AUTOSAR XML (schema 4-1-3)
standard types defined: boolean, uint16, uint8
package /UAES/ASW/ApplicationDataTypes
  app type Curr_Ampr_u16: category=VALUE, sw-calibration-access=READ-WRITE, compu {phys=raw*0.1; unit A}, range raw 0..65535, unit=A
package /UAES/ASW/CompuMethods
  compu method CM_boolean: 0=FALSE, 1=TRUE
package /UAES/ASW/DataTypeMappingSets
  data type mapping set DTMS_KL15PwrSplyComCnvRx: data-type-map{application-data-type=Curr_Ampr_u16, implementation-data-type=uint16}
  data type mapping set DTMS_ZCUTAdpr: data-type-map{application-data-type=Curr_Ampr_u16, implementation-data-type=uint16}
package /UAES/ASW/ImplementationDataTypes
  impl type rt_Array_uint8_29: category=ARRAY
    element rt_Array_uint8_29: array-size=29, array-size-semantics=FIXED-SIZE, implementation-data-type=uint8
package /UAES/ASW/PortInterfaces
  client server interface NMW_tGetAllCurrentComModeRTE
    operation Operation: possible-error=NMW_tGetAllCurrentComModeRTE/NmChannelIndexError
      arg Status: type=boolean, direction=OUT, server-argument-impl-policy=USE-ARGUMENT-TYPE
    error NmChannelIndexError: error-code=1
  client server interface NMW_tGetCurrentComModeRTE
    operation Operation: possible-error=NMW_tGetCurrentComModeRTE/NmChannelIndexError
      arg ComMChannel: type=uint8, direction=IN, server-argument-impl-policy=USE-ARGUMENT-TYPE
      arg ChannelStatus: type=boolean, direction=OUT, server-argument-impl-policy=USE-ARGUMENT-TYPE
    error NmChannelIndexError: error-code=1
  95 x sender receiver interface:
    ComRx_bBCS_VehSpd_TiOut: invalidation-policy{data-element=ComRx_bBCS_VehSpd_TiOut/Val, handle-invalid=DONT-INVALIDATE}
      data Val: sw-calibration-access=READ-ONLY, range raw 0..1, type=boolean
    ComRx_bBCS_VehSpdVD: invalidation-policy{data-element=ComRx_bBCS_VehSpdVD/Val, handle-invalid=DONT-INVALIDATE}
      data Val: sw-calibration-access=READ-ONLY, type=boolean
    ComRx_bBCS_VehSpdVD_TiOut: invalidation-policy{data-element=ComRx_bBCS_VehSpdVD_TiOut/Val, handle-invalid=DONT-INVALIDATE}
      data Val: sw-calibration-access=READ-ONLY, range raw 0..1, type=boolean
    ComRx_bEL_PositionLightTimingOFFCfg: invalidation-policy{data-element=ComRx_bEL_PositionLightTimingOFFCfg/Val, handle-invalid=DONT-INVALIDATE}
      data Val: sw-calibration-access=READ-ONLY, type=boolean
    ComRx_bEL_RLPositionLightCtrlCmd: invalidation-policy{data-element=ComRx_bEL_RLPositionLightCtrlCmd/Val, handle-invalid=DONT-INVALIDATE}
      data Val: sw-calibration-access=READ-ONLY, type=boolean
    ComRx_bEL_RRPositionLightCtrlCmd: invalidation-policy{data-element=ComRx_bEL_RRPositionLightCtrlCmd/Val, handle-invalid=DONT-INVALIDATE}
      data Val: sw-calibration-access=READ-ONLY, type=boolean
    ComRx_bIPDS_AMPPowerSup_TiOut: invalidation-policy{data-element=ComRx_bIPDS_AMPPowerSup_TiOut/Val, handle-invalid=DONT-INVALIDATE}
      data Val: sw-calibration-access=READ-ONLY, range raw 0..1, type=boolean
    ComRx_bIPDS_InverterPowerSup_TiOut: invalidation-policy{data-element=ComRx_bIPDS_InverterPowerSup_TiOut/Val, handle-invalid=DONT-INVALIDATE}
      data Val: sw-calibration-access=READ-ONLY, range raw 0..1, type=boolean
    ComRx_bIPDS_KL15T1PowerSup_TiOut: invalidation-policy{data-element=ComRx_bIPDS_KL15T1PowerSup_TiOut/Val, handle-invalid=DONT-INVALIDATE}
      data Val: sw-calibration-access=READ-ONLY, range raw 0..1, type=boolean
    ComRx_bIPDS_KL15T2PowerSup_TiOut: invalidation-policy{data-element=ComRx_bIPDS_KL15T2PowerSup_TiOut/Val, handle-invalid=DONT-INVALIDATE}
      data Val: sw-calibration-access=READ-ONLY, range raw 0..1, type=boolean
    ComRx_bIPDS_PCUPowerSup_TiOut: invalidation-policy{data-element=ComRx_bIPDS_PCUPowerSup_TiOut/Val, handle-invalid=DONT-INVALIDATE}
      data Val: sw-calibration-access=READ-ONLY, range raw 0..1, type=boolean
    ComRx_bIPDS_Rear12VPowerSup_TiOut: invalidation-policy{data-element=ComRx_bIPDS_Rear12VPowerSup_TiOut/Val, handle-invalid=DONT-INVALIDATE}
      data Val: sw-calibration-access=READ-ONLY, range raw 0..1, type=boolean
    ComRx_bIPDS_RearBlowerPowerSup_TiOut: invalidation-policy{data-element=ComRx_bIPDS_RearBlowerPowerSup_TiOut/Val, handle-invalid=DONT-INVALIDATE}
      data Val: sw-calibration-access=READ-ONLY, range raw 0..1, type=boolean
    ComRx_bIPDS_RearCtrlPanelPowerSup_TiOut: invalidation-policy{data-element=ComRx_bIPDS_RearCtrlPanelPowerSup_TiOut/Val, handle-invalid=DONT-INVALIDATE}
      data Val: sw-calibration-access=READ-ONLY, range raw 0..1, type=boolean
    ComRx_bIPDS_RearEOPPowerSup_TiOut: invalidation-policy{data-element=ComRx_bIPDS_RearEOPPowerSup_TiOut/Val, handle-invalid=DONT-INVALIDATE}
      data Val: sw-calibration-access=READ-ONLY, range raw 0..1, type=boolean
    ComRx_bIPDS_RearMotorPowerSup_TiOut: invalidation-policy{data-element=ComRx_bIPDS_RearMotorPowerSup_TiOut/Val, handle-invalid=DONT-INVALIDATE}
      data Val: sw-calibration-access=READ-ONLY, range raw 0..1, type=boolean
    ComRx_bIPDS_RearRadarPowerSup_TiOut: invalidation-policy{data-element=ComRx_bIPDS_RearRadarPowerSup_TiOut/Val, handle-invalid=DONT-INVALIDATE}
      data Val: sw-calibration-access=READ-ONLY, range raw 0..1, type=boolean
    ComRx_bIPDS_RLALampCtlUnitPowerSup_TiOut: invalidation-policy{data-element=ComRx_bIPDS_RLALampCtlUnitPowerSup_TiOut/Val, handle-invalid=DONT-INVALIDATE}
      data Val: sw-calibration-access=READ-ONLY, range raw 0..1, type=boolean
    ComRx_bIPDS_RLBLampCtlUnitPowerSup_TiOut: invalidation-policy{data-element=ComRx_bIPDS_RLBLampCtlUnitPowerSup_TiOut/Val, handle-invalid=DONT-INVALIDATE}
      data Val: sw-calibration-access=READ-ONLY, range raw 0..1, type=boolean
    ComRx_bIPDS_RMPowerSup_TiOut: invalidation-policy{data-element=ComRx_bIPDS_RMPowerSup_TiOut/Val, handle-invalid=DONT-INVALIDATE}
      data Val: sw-calibration-access=READ-ONLY, range raw 0..1, type=boolean
    ComRx_bIPDS_RRALampCtlUnitPowerSup_TiOut: invalidation-policy{data-element=ComRx_bIPDS_RRALampCtlUnitPowerSup_TiOut/Val, handle-invalid=DONT-INVALIDATE}
      data Val: sw-calibration-access=READ-ONLY, range raw 0..1, type=boolean
    ComRx_bIPDS_RRBLampCtlUnitPowerSup_TiOut: invalidation-policy{data-element=ComRx_bIPDS_RRBLampCtlUnitPowerSup_TiOut/Val, handle-invalid=DONT-INVALIDATE}
      data Val: sw-calibration-access=READ-ONLY, range raw 0..1, type=boolean
    ComRx_bUMM_UsageModeSt_TiOut: invalidation-policy{data-element=ComRx_bUMM_UsageModeSt_TiOut/Val, handle-invalid=DONT-INVALIDATE}
      data Val: sw-calibration-access=READ-ONLY, range raw 0..1, type=boolean
    ComRx_u16BCS_VehSpd: invalidation-policy{data-element=ComRx_u16BCS_VehSpd/Val, handle-invalid=DONT-INVALIDATE}
      data Val: sw-calibration-access=READ-ONLY, type=uint16
    ComRx_u8IPDS_AMPPowerSup: invalidation-policy{data-element=ComRx_u8IPDS_AMPPowerSup/Val, handle-invalid=DONT-INVALIDATE}
      data Val: sw-calibration-access=READ-ONLY, range raw 0..255, type=uint8
    ComRx_u8IPDS_AMPPowerSupTime: invalidation-policy{data-element=ComRx_u8IPDS_AMPPowerSupTime/Val, handle-invalid=DONT-INVALIDATE}
      data Val: sw-calibration-access=READ-ONLY, range raw 0..255, type=uint8
    ComRx_u8IPDS_AMPPowerSupTime_RcvCnt: invalidation-policy{data-element=ComRx_u8IPDS_AMPPowerSupTime_RcvCnt/Val, handle-invalid=DONT-INVALIDATE}
      data Val: sw-calibration-access=READ-ONLY, range raw 0..255, type=uint8
    ComRx_u8IPDS_InverterPowerSup: invalidation-policy{data-element=ComRx_u8IPDS_InverterPowerSup/Val, handle-invalid=DONT-INVALIDATE}
      data Val: sw-calibration-access=READ-ONLY, range raw 0..255, type=uint8
    ComRx_u8IPDS_InverterPowerSupTime: invalidation-policy{data-element=ComRx_u8IPDS_InverterPowerSupTime/Val, handle-invalid=DONT-INVALIDATE}
      data Val: sw-calibration-access=READ-ONLY, range raw 0..255, type=uint8
    ComRx_u8IPDS_InverterPowerSupTime_RcvCnt: invalidation-policy{data-element=ComRx_u8IPDS_InverterPowerSupTime_RcvCnt/Val, handle-invalid=DONT-INVALIDATE}
      data Val: sw-calibration-access=READ-ONLY, range raw 0..255, type=uint8
    ComRx_u8IPDS_KL15T1PowerSup: invalidation-policy{data-element=ComRx_u8IPDS_KL15T1PowerSup/Val, handle-invalid=DONT-INVALIDATE}
      data Val: sw-calibration-access=READ-ONLY, range raw 0..255, type=uint8
    ComRx_u8IPDS_KL15T1PowerSupTime: invalidation-policy{data-element=ComRx_u8IPDS_KL15T1PowerSupTime/Val, handle-invalid=DONT-INVALIDATE}
      data Val: sw-calibration-access=READ-ONLY, range raw 0..255, type=uint8
    ComRx_u8IPDS_KL15T1PowerSupTime_RcvCnt: invalidation-policy{data-element=ComRx_u8IPDS_KL15T1PowerSupTime_RcvCnt/Val, handle-invalid=DONT-INVALIDATE}
      data Val: sw-calibration-access=READ-ONLY, range raw 0..255, type=uint8
    ComRx_u8IPDS_KL15T2PowerSup: invalidation-policy{data-element=ComRx_u8IPDS_KL15T2PowerSup/Val, handle-invalid=DONT-INVALIDATE}
      data Val: sw-calibration-access=READ-ONLY, range raw 0..255, type=uint8
    ComRx_u8IPDS_KL15T2PowerSupTime: invalidation-policy{data-element=ComRx_u8IPDS_KL15T2PowerSupTime/Val, handle-invalid=DONT-INVALIDATE}
      data Val: sw-calibration-access=READ-ONLY, range raw 0..255, type=uint8
    ComRx_u8IPDS_KL15T2PowerSupTime_RcvCnt: invalidation-policy{data-element=ComRx_u8IPDS_KL15T2PowerSupTime_RcvCnt/Val, handle-invalid=DONT-INVALIDATE}
      data Val: sw-calibration-access=READ-ONLY, range raw 0..255, type=uint8
    ComRx_u8IPDS_PASPowerSup: invalidation-policy{data-element=ComRx_u8IPDS_PASPowerSup/Val, handle-invalid=DONT-INVALIDATE}
      data Val: sw-calibration-access=READ-ONLY, range raw 0..255, type=uint8
    ComRx_u8IPDS_PASPowerSupTime: invalidation-policy{data-element=ComRx_u8IPDS_PASPowerSupTime/Val, handle-invalid=DONT-INVALIDATE}
      data Val: sw-calibration-access=READ-ONLY, range raw 0..255, type=uint8
    ComRx_u8IPDS_PASPowerSupTime_RcvCnt: invalidation-policy{data-element=ComRx_u8IPDS_PASPowerSupTime_RcvCnt/Val, handle-invalid=DONT-INVALIDATE}
      data Val: sw-calibration-access=READ-ONLY, range raw 0..255, type=uint8
    ComRx_u8IPDS_PCUPowerSup: invalidation-policy{data-element=ComRx_u8IPDS_PCUPowerSup/Val, handle-invalid=DONT-INVALIDATE}
      data Val: sw-calibration-access=READ-ONLY, range raw 0..255, type=uint8
    ComRx_u8IPDS_PCUPowerSupTime: invalidation-policy{data-element=ComRx_u8IPDS_PCUPowerSupTime/Val, handle-invalid=DONT-INVALIDATE}
      data Val: sw-calibration-access=READ-ONLY, range raw 0..255, type=uint8
    ComRx_u8IPDS_PCUPowerSupTime_RcvCnt: invalidation-policy{data-element=ComRx_u8IPDS_PCUPowerSupTime_RcvCnt/Val, handle-invalid=DONT-INVALIDATE}
      data Val: sw-calibration-access=READ-ONLY, range raw 0..255, type=uint8
    ComRx_u8IPDS_Rear12VPowerSup: invalidation-policy{data-element=ComRx_u8IPDS_Rear12VPowerSup/Val, handle-invalid=DONT-INVALIDATE}
      data Val: sw-calibration-access=READ-ONLY, range raw 0..255, type=uint8
    ComRx_u8IPDS_Rear12VPowerSupTime: invalidation-policy{data-element=ComRx_u8IPDS_Rear12VPowerSupTime/Val, handle-invalid=DONT-INVALIDATE}
      data Val: sw-calibration-access=READ-ONLY, range raw 0..255, type=uint8
    ComRx_u8IPDS_Rear12VPowerSupTime_RcvCnt: invalidation-policy{data-element=ComRx_u8IPDS_Rear12VPowerSupTime_RcvCnt/Val, handle-invalid=DONT-INVALIDATE}
      data Val: sw-calibration-access=READ-ONLY, range raw 0..255, type=uint8
    ComRx_u8IPDS_RearBlowerPowerSup: invalidation-policy{data-element=ComRx_u8IPDS_RearBlowerPowerSup/Val, handle-invalid=DONT-INVALIDATE}
      data Val: sw-calibration-access=READ-ONLY, range raw 0..255, type=uint8
    ComRx_u8IPDS_RearBlowerPowerSupTime: invalidation-policy{data-element=ComRx_u8IPDS_RearBlowerPowerSupTime/Val, handle-invalid=DONT-INVALIDATE}
      data Val: sw-calibration-access=READ-ONLY, range raw 0..255, type=uint8
    ComRx_u8IPDS_RearBlowerPowerSupTime_RcvCnt: invalidation-policy{data-element=ComRx_u8IPDS_RearBlowerPowerSupTime_RcvCnt/Val, handle-invalid=DONT-INVALIDATE}
      data Val: sw-calibration-access=READ-ONLY, range raw 0..255, type=uint8
    ComRx_u8IPDS_RearCtrlPanelPowerSup: invalidation-policy{data-element=ComRx_u8IPDS_RearCtrlPanelPowerSup/Val, handle-invalid=DONT-INVALIDATE}
      data Val: sw-calibration-access=READ-ONLY, range raw 0..255, type=uint8
    ComRx_u8IPDS_RearCtrlPanelPowerSupTime: invalidation-policy{data-element=ComRx_u8IPDS_RearCtrlPanelPowerSupTime/Val, handle-invalid=DONT-INVALIDATE}
      data Val: sw-calibration-access=READ-ONLY, range raw 0..255, type=uint8
    ComRx_u8IPDS_RearCtrlPanelPowerSupTime_RcvCnt: invalidation-policy{data-element=ComRx_u8IPDS_RearCtrlPanelPowerSupTime_RcvCnt/Val, handle-invalid=DONT-INVALIDATE}
      data Val: sw-calibration-access=READ-ONLY, range raw 0..255, type=uint8
    ComRx_u8IPDS_RearEOPPowerSup: invalidation-policy{data-element=ComRx_u8IPDS_RearEOPPowerSup/Val, handle-invalid=DONT-INVALIDATE}
      data Val: sw-calibration-access=READ-ONLY, range raw 0..255, type=uint8
    ComRx_u8IPDS_RearEOPPowerSupTime: invalidation-policy{data-element=ComRx_u8IPDS_RearEOPPowerSupTime/Val, handle-invalid=DONT-INVALIDATE}
      data Val: sw-calibration-access=READ-ONLY, range raw 0..255, type=uint8
    ComRx_u8IPDS_RearEOPPowerSupTime_RcvCnt: invalidation-policy{data-element=ComRx_u8IPDS_RearEOPPowerSupTime_RcvCnt/Val, handle-invalid=DONT-INVALIDATE}
      data Val: sw-calibration-access=READ-ONLY, range raw 0..255, type=uint8
    ComRx_u8IPDS_RearMotorPowerSup: invalidation-policy{data-element=ComRx_u8IPDS_RearMotorPowerSup/Val, handle-invalid=DONT-INVALIDATE}
      data Val: sw-calibration-access=READ-ONLY, range raw 0..255, type=uint8
    ComRx_u8IPDS_RearMotorPowerSupTime: invalidation-policy{data-element=ComRx_u8IPDS_RearMotorPowerSupTime/Val, handle-invalid=DONT-INVALIDATE}
      data Val: sw-calibration-access=READ-ONLY, range raw 0..255, type=uint8
    ComRx_u8IPDS_RearMotorPowerSupTime_RcvCnt: invalidation-policy{data-element=ComRx_u8IPDS_RearMotorPowerSupTime_RcvCnt/Val, handle-invalid=DONT-INVALIDATE}
      data Val: sw-calibration-access=READ-ONLY, range raw 0..255, type=uint8
    ComRx_u8IPDS_RearRadarPowerSup: invalidation-policy{data-element=ComRx_u8IPDS_RearRadarPowerSup/Val, handle-invalid=DONT-INVALIDATE}
      data Val: sw-calibration-access=READ-ONLY, range raw 0..255, type=uint8
    ComRx_u8IPDS_RearRadarPowerSupTime: invalidation-policy{data-element=ComRx_u8IPDS_RearRadarPowerSupTime/Val, handle-invalid=DONT-INVALIDATE}
      data Val: sw-calibration-access=READ-ONLY, range raw 0..255, type=uint8
    ComRx_u8IPDS_RearRadarPowerSupTime_RcvCnt: invalidation-policy{data-element=ComRx_u8IPDS_RearRadarPowerSupTime_RcvCnt/Val, handle-invalid=DONT-INVALIDATE}
      data Val: sw-calibration-access=READ-ONLY, range raw 0..255, type=uint8
    ComRx_u8IPDS_RLALampCtlUnitPowerSup: invalidation-policy{data-element=ComRx_u8IPDS_RLALampCtlUnitPowerSup/Val, handle-invalid=DONT-INVALIDATE}
      data Val: sw-calibration-access=READ-ONLY, range raw 0..255, type=uint8
    ComRx_u8IPDS_RLALampCtlUnitPowerSupTime: invalidation-policy{data-element=ComRx_u8IPDS_RLALampCtlUnitPowerSupTime/Val, handle-invalid=DONT-INVALIDATE}
      data Val: sw-calibration-access=READ-ONLY, range raw 0..255, type=uint8
    ComRx_u8IPDS_RLALampCtlUnitPowerSupTime_RcvCnt: invalidation-policy{data-element=ComRx_u8IPDS_RLALampCtlUnitPowerSupTime_RcvCnt/Val, handle-invalid=DONT-INVALIDATE}
      data Val: sw-calibration-access=READ-ONLY, range raw 0..255, type=uint8
    ComRx_u8IPDS_RLBLampCtlUnitPowerSup: invalidation-policy{data-element=ComRx_u8IPDS_RLBLampCtlUnitPowerSup/Val, handle-invalid=DONT-INVALIDATE}
      data Val: sw-calibration-access=READ-ONLY, range raw 0..255, type=uint8
    ComRx_u8IPDS_RLBLampCtlUnitPowerSupTime: invalidation-policy{data-element=ComRx_u8IPDS_RLBLampCtlUnitPowerSupTime/Val, handle-invalid=DONT-INVALIDATE}
      data Val: sw-calibration-access=READ-ONLY, range raw 0..255, type=uint8
    ComRx_u8IPDS_RLBLampCtlUnitPowerSupTime_RcvCnt: invalidation-policy{data-element=ComRx_u8IPDS_RLBLampCtlUnitPowerSupTime_RcvCnt/Val, handle-invalid=DONT-INVALIDATE}
      data Val: sw-calibration-access=READ-ONLY, range raw 0..255, type=uint8
    ComRx_u8IPDS_RMPowerSup: invalidation-policy{data-element=ComRx_u8IPDS_RMPowerSup/Val, handle-invalid=DONT-INVALIDATE}
      data Val: sw-calibration-access=READ-ONLY, range raw 0..255, type=uint8
    ComRx_u8IPDS_RMPowerSupTime: invalidation-policy{data-element=ComRx_u8IPDS_RMPowerSupTime/Val, handle-invalid=DONT-INVALIDATE}
      data Val: sw-calibration-access=READ-ONLY, range raw 0..255, type=uint8
    ComRx_u8IPDS_RMPowerSupTime_RcvCnt: invalidation-policy{data-element=ComRx_u8IPDS_RMPowerSupTime_RcvCnt/Val, handle-invalid=DONT-INVALIDATE}
      data Val: sw-calibration-access=READ-ONLY, range raw 0..255, type=uint8
    ComRx_u8IPDS_RRALampCtlUnitPowerSup: invalidation-policy{data-element=ComRx_u8IPDS_RRALampCtlUnitPowerSup/Val, handle-invalid=DONT-INVALIDATE}
      data Val: sw-calibration-access=READ-ONLY, range raw 0..255, type=uint8
    ComRx_u8IPDS_RRALampCtlUnitPowerSupTime: invalidation-policy{data-element=ComRx_u8IPDS_RRALampCtlUnitPowerSupTime/Val, handle-invalid=DONT-INVALIDATE}
      data Val: sw-calibration-access=READ-ONLY, range raw 0..255, type=uint8
    ComRx_u8IPDS_RRALampCtlUnitPowerSupTime_RcvCnt: invalidation-policy{data-element=ComRx_u8IPDS_RRALampCtlUnitPowerSupTime_RcvCnt/Val, handle-invalid=DONT-INVALIDATE}
      data Val: sw-calibration-access=READ-ONLY, range raw 0..255, type=uint8
    ComRx_u8IPDS_RRBLampCtlUnitPowerSup: invalidation-policy{data-element=ComRx_u8IPDS_RRBLampCtlUnitPowerSup/Val, handle-invalid=DONT-INVALIDATE}
      data Val: sw-calibration-access=READ-ONLY, range raw 0..255, type=uint8
    ComRx_u8IPDS_RRBLampCtlUnitPowerSupTime: invalidation-policy{data-element=ComRx_u8IPDS_RRBLampCtlUnitPowerSupTime/Val, handle-invalid=DONT-INVALIDATE}
      data Val: sw-calibration-access=READ-ONLY, range raw 0..255, type=uint8
    ComRx_u8IPDS_RRBLampCtlUnitPowerSupTime_RcvCnt: invalidation-policy{data-element=ComRx_u8IPDS_RRBLampCtlUnitPowerSupTime_RcvCnt/Val, handle-invalid=DONT-INVALIDATE}
      data Val: sw-calibration-access=READ-ONLY, range raw 0..255, type=uint8
    ComRx_u8UMM_UsageModeSt: invalidation-policy{data-element=ComRx_u8UMM_UsageModeSt/Val, handle-invalid=DONT-INVALIDATE}
      data Val: sw-calibration-access=READ-ONLY, type=uint8
    ComRx_u8VMM_OTAModeSt: invalidation-policy{data-element=ComRx_u8VMM_OTAModeSt/Val, handle-invalid=DONT-INVALIDATE}
      data Val: sw-calibration-access=READ-ONLY, range raw 0..255, type=uint8
    gPRM_bPositionLightTimingOFFEnableCfg: invalidation-policy{data-element=gPRM_bPositionLightTimingOFFEnableCfg/Val, handle-invalid=DONT-INVALIDATE}
      data Val: sw-calibration-access=READ-ONLY, type=boolean
    gPRM_u8VehicleTypeCfg: invalidation-policy{data-element=gPRM_u8VehicleTypeCfg/Val, handle-invalid=DONT-INVALIDATE}
      data Val: sw-calibration-access=READ-ONLY, range raw 0..255, type=uint8
    gPRM_u8VehRLCM: invalidation-policy{data-element=gPRM_u8VehRLCM/Val, handle-invalid=DONT-INVALIDATE}
      data Val: sw-calibration-access=READ-ONLY, range raw 0..255, type=uint8
    PwrSply_au8PwrSup: invalidation-policy{data-element=PwrSply_au8PwrSup/Val, handle-invalid=DONT-INVALIDATE}
      data Val: sw-calibration-access=READ-ONLY, type=rt_Array_uint8_29
    PwrSply_au8PwrSupTime: invalidation-policy{data-element=PwrSply_au8PwrSupTime/Val, handle-invalid=DONT-INVALIDATE}
      data Val: sw-calibration-access=READ-ONLY, type=rt_Array_uint8_29
    PwrSply_au8PwrSupTime_RcvCnt: invalidation-policy{data-element=PwrSply_au8PwrSupTime_RcvCnt/Val, handle-invalid=DONT-INVALIDATE}
      data Val: sw-calibration-access=READ-ONLY, type=rt_Array_uint8_29
    PwrSply_bCCULostComm: invalidation-policy{data-element=PwrSply_bCCULostComm/Val, handle-invalid=DONT-INVALIDATE}
      data Val: sw-calibration-access=READ-ONLY, range raw 0..1, type=boolean
    PwrSply_bNetSleepFlag: invalidation-policy{data-element=PwrSply_bNetSleepFlag/Val, handle-invalid=DONT-INVALIDATE}
      data Val: sw-calibration-access=READ-ONLY, range raw 0..1, type=boolean
    PwrSply_bPositionLightCtrlCmd01: invalidation-policy{data-element=PwrSply_bPositionLightCtrlCmd01/Val, handle-invalid=DONT-INVALIDATE}
      data Val: sw-calibration-access=READ-ONLY, type=boolean
    PwrSply_bPositionLightCtrlCmd02: invalidation-policy{data-element=PwrSply_bPositionLightCtrlCmd02/Val, handle-invalid=DONT-INVALIDATE}
      data Val: sw-calibration-access=READ-ONLY, type=boolean
    PwrSply_bPositionLightCtrlCmd03: invalidation-policy{data-element=PwrSply_bPositionLightCtrlCmd03/Val, handle-invalid=DONT-INVALIDATE}
      data Val: sw-calibration-access=READ-ONLY, type=boolean
    PwrSply_bPositionLightCtrlCmd04: invalidation-policy{data-element=PwrSply_bPositionLightCtrlCmd04/Val, handle-invalid=DONT-INVALIDATE}
      data Val: sw-calibration-access=READ-ONLY, type=boolean
    PwrSply_bPositionLightTimingOFFEnableCfg: invalidation-policy{data-element=PwrSply_bPositionLightTimingOFFEnableCfg/Val, handle-invalid=DONT-INVALIDATE}
      data Val: sw-calibration-access=READ-ONLY, type=boolean
    PwrSply_bVehSpdTkOvr: invalidation-policy{data-element=PwrSply_bVehSpdTkOvr/Val, handle-invalid=DONT-INVALIDATE}
      data Val: sw-calibration-access=READ-ONLY, range raw 0..1, type=boolean
    PwrSply_u8UMM_UsageModeSt: invalidation-policy{data-element=PwrSply_u8UMM_UsageModeSt/Val, handle-invalid=DONT-INVALIDATE}
      data Val: sw-calibration-access=READ-ONLY, range raw 0..255, type=uint8
    PwrSply_u8VehicleTypeCfg: invalidation-policy{data-element=PwrSply_u8VehicleTypeCfg/Val, handle-invalid=DONT-INVALIDATE}
      data Val: sw-calibration-access=READ-ONLY, range raw 0..255, type=uint8
    PwrSply_u8VehRLCM: invalidation-policy{data-element=PwrSply_u8VehRLCM/Val, handle-invalid=DONT-INVALIDATE}
      data Val: sw-calibration-access=READ-ONLY, type=uint8
    PwrSply_u8VMM_OTAModeSt: invalidation-policy{data-element=PwrSply_u8VMM_OTAModeSt/Val, handle-invalid=DONT-INVALIDATE}
      data Val: sw-calibration-access=READ-ONLY, range raw 0..255, type=uint8
package /UAES/ASW/SwComponentTypes
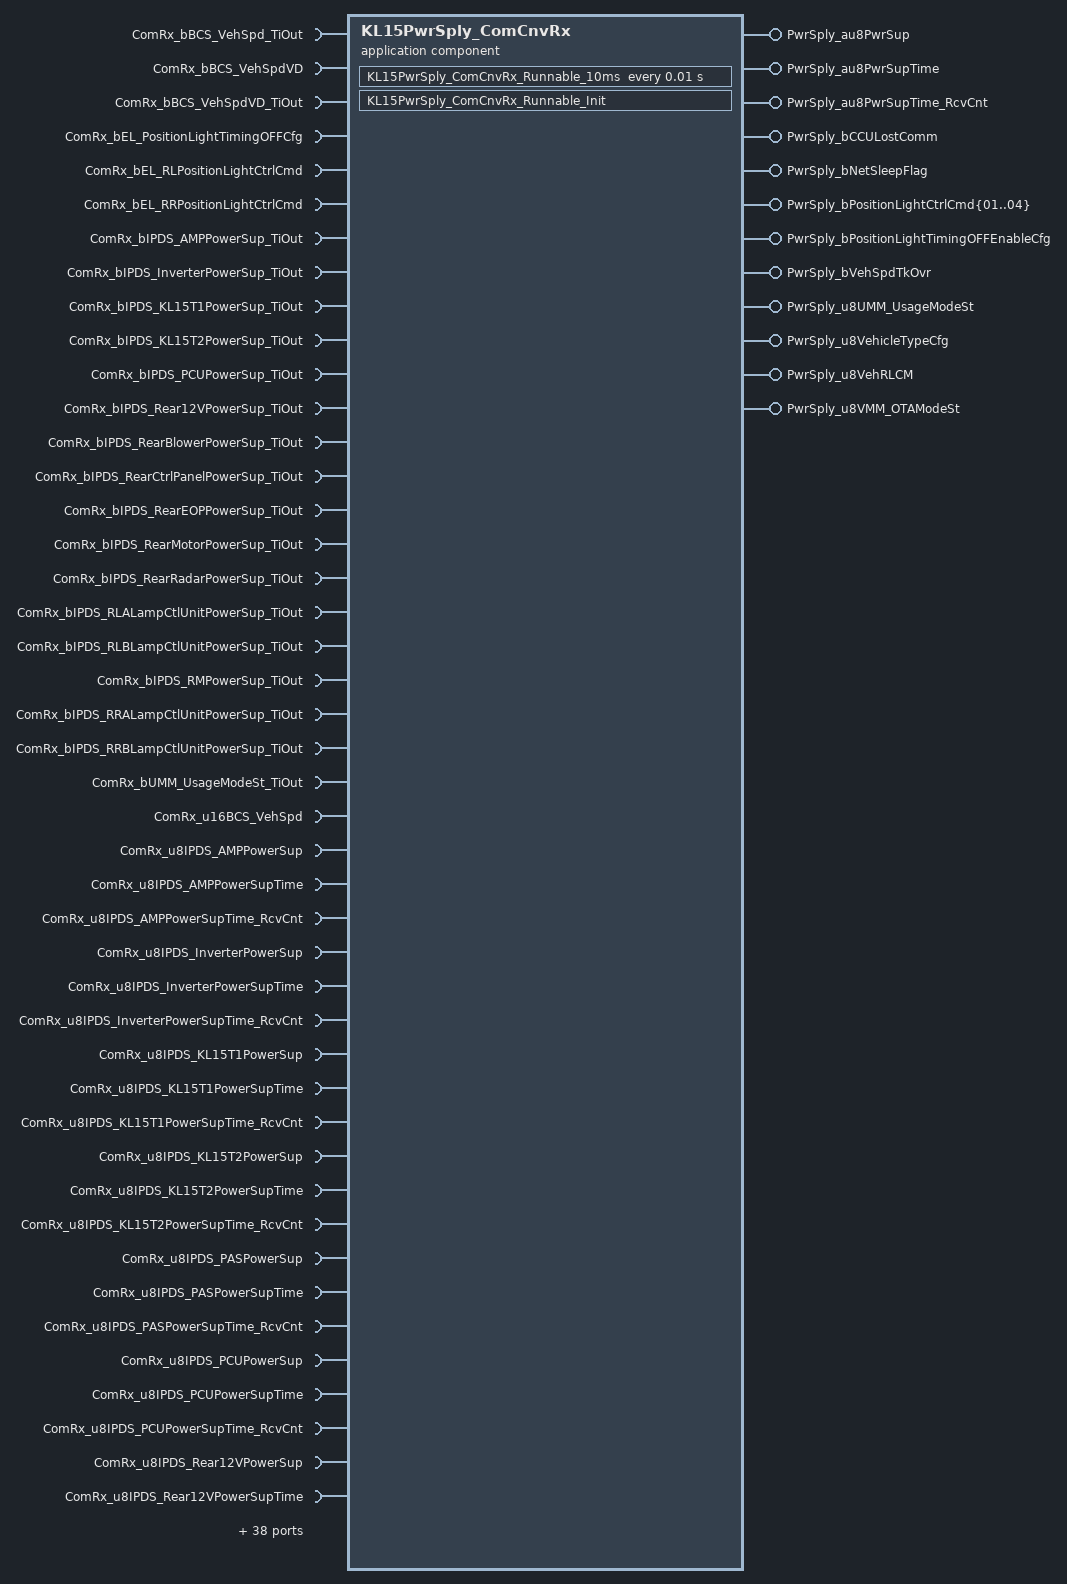
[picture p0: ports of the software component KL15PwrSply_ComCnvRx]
  application sw component type KL15PwrSply_ComCnvRx
    15 x provide port:
      PwrSply_au8PwrSup: nonqueued-sender-com-spec{data-element=PwrSply_au8PwrSup/Val, init-value=29 x 0}, provided-interface=PwrSply_au8PwrSup
      PwrSply_au8PwrSupTime: nonqueued-sender-com-spec{data-element=PwrSply_au8PwrSupTime/Val, init-value=29 x 0}, provided-interface=PwrSply_au8PwrSupTime
      PwrSply_au8PwrSupTime_RcvCnt: nonqueued-sender-com-spec{data-element=PwrSply_au8PwrSupTime_RcvCnt/Val, init-value=29 x 0}, provided-interface=PwrSply_au8PwrSupTime_RcvCnt
      PwrSply_bCCULostComm: nonqueued-sender-com-spec{data-element=PwrSply_bCCULostComm/Val, init-value=0}, provided-interface=PwrSply_bCCULostComm
      PwrSply_bNetSleepFlag: nonqueued-sender-com-spec{data-element=PwrSply_bNetSleepFlag/Val, init-value=0}, provided-interface=PwrSply_bNetSleepFlag
      PwrSply_bPositionLightCtrlCmd{01..04}: nonqueued-sender-com-spec{data-element=PwrSply_bPositionLightCtrlCmd{01..04}/Val, init-value=0}, provided-interface=PwrSply_bPositionLightCtrlCmd{01..04}
      PwrSply_bPositionLightTimingOFFEnableCfg: nonqueued-sender-com-spec{data-element=PwrSply_bPositionLightTimingOFFEnableCfg/Val, init-value=0}, provided-interface=PwrSply_bPositionLightTimingOFFEnableCfg
      PwrSply_bVehSpdTkOvr: nonqueued-sender-com-spec{data-element=PwrSply_bVehSpdTkOvr/Val, init-value=0}, provided-interface=PwrSply_bVehSpdTkOvr
      PwrSply_u8UMM_UsageModeSt: nonqueued-sender-com-spec{data-element=PwrSply_u8UMM_UsageModeSt/Val, init-value=0}, provided-interface=PwrSply_u8UMM_UsageModeSt
      PwrSply_u8VehicleTypeCfg: nonqueued-sender-com-spec{data-element=PwrSply_u8VehicleTypeCfg/Val, init-value=0}, provided-interface=PwrSply_u8VehicleTypeCfg
      PwrSply_u8VehRLCM: nonqueued-sender-com-spec{data-element=PwrSply_u8VehRLCM/Val, init-value=0}, provided-interface=PwrSply_u8VehRLCM
      PwrSply_u8VMM_OTAModeSt: nonqueued-sender-com-spec{data-element=PwrSply_u8VMM_OTAModeSt/Val, init-value=0}, provided-interface=PwrSply_u8VMM_OTAModeSt
    82 x require port:
      ComRx_bBCS_VehSpd_TiOut: nonqueued-receiver-com-spec{data-element=ComRx_bBCS_VehSpd_TiOut/Val, filter=data-filter-type=ALWAYS, init-value=0}, required-interface=ComRx_bBCS_VehSpd_TiOut
      ComRx_bBCS_VehSpdVD: nonqueued-receiver-com-spec{data-element=ComRx_bBCS_VehSpdVD/Val, filter=data-filter-type=ALWAYS, init-value=0}, required-interface=ComRx_bBCS_VehSpdVD
      ComRx_bBCS_VehSpdVD_TiOut: nonqueued-receiver-com-spec{data-element=ComRx_bBCS_VehSpdVD_TiOut/Val, filter=data-filter-type=ALWAYS, init-value=0}, required-interface=ComRx_bBCS_VehSpdVD_TiOut
      ComRx_bEL_PositionLightTimingOFFCfg: nonqueued-receiver-com-spec{data-element=ComRx_bEL_PositionLightTimingOFFCfg/Val, filter=data-filter-type=ALWAYS, init-value=0}, required-interface=ComRx_bEL_PositionLightTimingOFFCfg
      ComRx_bEL_RLPositionLightCtrlCmd: nonqueued-receiver-com-spec{data-element=ComRx_bEL_RLPositionLightCtrlCmd/Val, filter=data-filter-type=ALWAYS, init-value=0}, required-interface=ComRx_bEL_RLPositionLightCtrlCmd
      ComRx_bEL_RRPositionLightCtrlCmd: nonqueued-receiver-com-spec{data-element=ComRx_bEL_RRPositionLightCtrlCmd/Val, filter=data-filter-type=ALWAYS, init-value=0}, required-interface=ComRx_bEL_RRPositionLightCtrlCmd
      ComRx_bIPDS_AMPPowerSup_TiOut: nonqueued-receiver-com-spec{data-element=ComRx_bIPDS_AMPPowerSup_TiOut/Val, filter=data-filter-type=ALWAYS, init-value=0}, required-interface=ComRx_bIPDS_AMPPowerSup_TiOut
      ComRx_bIPDS_InverterPowerSup_TiOut: nonqueued-receiver-com-spec{data-element=ComRx_bIPDS_InverterPowerSup_TiOut/Val, filter=data-filter-type=ALWAYS, init-value=0}, required-interface=ComRx_bIPDS_InverterPowerSup_TiOut
      ComRx_bIPDS_KL15T1PowerSup_TiOut: nonqueued-receiver-com-spec{data-element=ComRx_bIPDS_KL15T1PowerSup_TiOut/Val, filter=data-filter-type=ALWAYS, init-value=0}, required-interface=ComRx_bIPDS_KL15T1PowerSup_TiOut
      ComRx_bIPDS_KL15T2PowerSup_TiOut: nonqueued-receiver-com-spec{data-element=ComRx_bIPDS_KL15T2PowerSup_TiOut/Val, filter=data-filter-type=ALWAYS, init-value=0}, required-interface=ComRx_bIPDS_KL15T2PowerSup_TiOut
      ComRx_bIPDS_PCUPowerSup_TiOut: nonqueued-receiver-com-spec{data-element=ComRx_bIPDS_PCUPowerSup_TiOut/Val, filter=data-filter-type=ALWAYS, init-value=0}, required-interface=ComRx_bIPDS_PCUPowerSup_TiOut
      ComRx_bIPDS_Rear12VPowerSup_TiOut: nonqueued-receiver-com-spec{data-element=ComRx_bIPDS_Rear12VPowerSup_TiOut/Val, filter=data-filter-type=ALWAYS, init-value=0}, required-interface=ComRx_bIPDS_Rear12VPowerSup_TiOut
      ComRx_bIPDS_RearBlowerPowerSup_TiOut: nonqueued-receiver-com-spec{data-element=ComRx_bIPDS_RearBlowerPowerSup_TiOut/Val, filter=data-filter-type=ALWAYS, init-value=0}, required-interface=ComRx_bIPDS_RearBlowerPowerSup_TiOut
      ComRx_bIPDS_RearCtrlPanelPowerSup_TiOut: nonqueued-receiver-com-spec{data-element=ComRx_bIPDS_RearCtrlPanelPowerSup_TiOut/Val, filter=data-filter-type=ALWAYS, init-value=0}, required-interface=ComRx_bIPDS_RearCtrlPanelPowerSup_TiOut
      ComRx_bIPDS_RearEOPPowerSup_TiOut: nonqueued-receiver-com-spec{data-element=ComRx_bIPDS_RearEOPPowerSup_TiOut/Val, filter=data-filter-type=ALWAYS, init-value=0}, required-interface=ComRx_bIPDS_RearEOPPowerSup_TiOut
      ComRx_bIPDS_RearMotorPowerSup_TiOut: nonqueued-receiver-com-spec{data-element=ComRx_bIPDS_RearMotorPowerSup_TiOut/Val, filter=data-filter-type=ALWAYS, init-value=0}, required-interface=ComRx_bIPDS_RearMotorPowerSup_TiOut
      ComRx_bIPDS_RearRadarPowerSup_TiOut: nonqueued-receiver-com-spec{data-element=ComRx_bIPDS_RearRadarPowerSup_TiOut/Val, filter=data-filter-type=ALWAYS, init-value=0}, required-interface=ComRx_bIPDS_RearRadarPowerSup_TiOut
      ComRx_bIPDS_RLALampCtlUnitPowerSup_TiOut: nonqueued-receiver-com-spec{data-element=ComRx_bIPDS_RLALampCtlUnitPowerSup_TiOut/Val, filter=data-filter-type=ALWAYS, init-value=0}, required-interface=ComRx_bIPDS_RLALampCtlUnitPowerSup_TiOut
      ComRx_bIPDS_RLBLampCtlUnitPowerSup_TiOut: nonqueued-receiver-com-spec{data-element=ComRx_bIPDS_RLBLampCtlUnitPowerSup_TiOut/Val, filter=data-filter-type=ALWAYS, init-value=0}, required-interface=ComRx_bIPDS_RLBLampCtlUnitPowerSup_TiOut
      ComRx_bIPDS_RMPowerSup_TiOut: nonqueued-receiver-com-spec{data-element=ComRx_bIPDS_RMPowerSup_TiOut/Val, filter=data-filter-type=ALWAYS, init-value=0}, required-interface=ComRx_bIPDS_RMPowerSup_TiOut
      ComRx_bIPDS_RRALampCtlUnitPowerSup_TiOut: nonqueued-receiver-com-spec{data-element=ComRx_bIPDS_RRALampCtlUnitPowerSup_TiOut/Val, filter=data-filter-type=ALWAYS, init-value=0}, required-interface=ComRx_bIPDS_RRALampCtlUnitPowerSup_TiOut
      ComRx_bIPDS_RRBLampCtlUnitPowerSup_TiOut: nonqueued-receiver-com-spec{data-element=ComRx_bIPDS_RRBLampCtlUnitPowerSup_TiOut/Val, filter=data-filter-type=ALWAYS, init-value=0}, required-interface=ComRx_bIPDS_RRBLampCtlUnitPowerSup_TiOut
      ComRx_bUMM_UsageModeSt_TiOut: nonqueued-receiver-com-spec{data-element=ComRx_bUMM_UsageModeSt_TiOut/Val, filter=data-filter-type=ALWAYS, init-value=0}, required-interface=ComRx_bUMM_UsageModeSt_TiOut
      ComRx_u16BCS_VehSpd: nonqueued-receiver-com-spec{data-element=ComRx_u16BCS_VehSpd/Val, filter=data-filter-type=ALWAYS, init-value=0}, required-interface=ComRx_u16BCS_VehSpd
      ComRx_u8IPDS_AMPPowerSup: nonqueued-receiver-com-spec{data-element=ComRx_u8IPDS_AMPPowerSup/Val, filter=data-filter-type=ALWAYS, init-value=0}, required-interface=ComRx_u8IPDS_AMPPowerSup
      ComRx_u8IPDS_AMPPowerSupTime: nonqueued-receiver-com-spec{data-element=ComRx_u8IPDS_AMPPowerSupTime/Val, filter=data-filter-type=ALWAYS, init-value=0}, required-interface=ComRx_u8IPDS_AMPPowerSupTime
      ComRx_u8IPDS_AMPPowerSupTime_RcvCnt: nonqueued-receiver-com-spec{data-element=ComRx_u8IPDS_AMPPowerSupTime_RcvCnt/Val, filter=data-filter-type=ALWAYS, init-value=0}, required-interface=ComRx_u8IPDS_AMPPowerSupTime_RcvCnt
      ComRx_u8IPDS_InverterPowerSup: nonqueued-receiver-com-spec{data-element=ComRx_u8IPDS_InverterPowerSup/Val, filter=data-filter-type=ALWAYS, init-value=0}, required-interface=ComRx_u8IPDS_InverterPowerSup
      ComRx_u8IPDS_InverterPowerSupTime: nonqueued-receiver-com-spec{data-element=ComRx_u8IPDS_InverterPowerSupTime/Val, filter=data-filter-type=ALWAYS, init-value=0}, required-interface=ComRx_u8IPDS_InverterPowerSupTime
      ComRx_u8IPDS_InverterPowerSupTime_RcvCnt: nonqueued-receiver-com-spec{data-element=ComRx_u8IPDS_InverterPowerSupTime_RcvCnt/Val, filter=data-filter-type=ALWAYS, init-value=0}, required-interface=ComRx_u8IPDS_InverterPowerSupTime_RcvCnt
      ComRx_u8IPDS_KL15T1PowerSup: nonqueued-receiver-com-spec{data-element=ComRx_u8IPDS_KL15T1PowerSup/Val, filter=data-filter-type=ALWAYS, init-value=0}, required-interface=ComRx_u8IPDS_KL15T1PowerSup
      ComRx_u8IPDS_KL15T1PowerSupTime: nonqueued-receiver-com-spec{data-element=ComRx_u8IPDS_KL15T1PowerSupTime/Val, filter=data-filter-type=ALWAYS, init-value=0}, required-interface=ComRx_u8IPDS_KL15T1PowerSupTime
      ComRx_u8IPDS_KL15T1PowerSupTime_RcvCnt: nonqueued-receiver-com-spec{data-element=ComRx_u8IPDS_KL15T1PowerSupTime_RcvCnt/Val, filter=data-filter-type=ALWAYS, init-value=0}, required-interface=ComRx_u8IPDS_KL15T1PowerSupTime_RcvCnt
      ComRx_u8IPDS_KL15T2PowerSup: nonqueued-receiver-com-spec{data-element=ComRx_u8IPDS_KL15T2PowerSup/Val, filter=data-filter-type=ALWAYS, init-value=0}, required-interface=ComRx_u8IPDS_KL15T2PowerSup
      ComRx_u8IPDS_KL15T2PowerSupTime: nonqueued-receiver-com-spec{data-element=ComRx_u8IPDS_KL15T2PowerSupTime/Val, filter=data-filter-type=ALWAYS, init-value=0}, required-interface=ComRx_u8IPDS_KL15T2PowerSupTime
      ComRx_u8IPDS_KL15T2PowerSupTime_RcvCnt: nonqueued-receiver-com-spec{data-element=ComRx_u8IPDS_KL15T2PowerSupTime_RcvCnt/Val, filter=data-filter-type=ALWAYS, init-value=0}, required-interface=ComRx_u8IPDS_KL15T2PowerSupTime_RcvCnt
      ComRx_u8IPDS_PASPowerSup: nonqueued-receiver-com-spec{data-element=ComRx_u8IPDS_PASPowerSup/Val, filter=data-filter-type=ALWAYS, init-value=0}, required-interface=ComRx_u8IPDS_PASPowerSup
      ComRx_u8IPDS_PASPowerSupTime: nonqueued-receiver-com-spec{data-element=ComRx_u8IPDS_PASPowerSupTime/Val, filter=data-filter-type=ALWAYS, init-value=0}, required-interface=ComRx_u8IPDS_PASPowerSupTime
      ComRx_u8IPDS_PASPowerSupTime_RcvCnt: nonqueued-receiver-com-spec{data-element=ComRx_u8IPDS_PASPowerSupTime_RcvCnt/Val, filter=data-filter-type=ALWAYS, init-value=0}, required-interface=ComRx_u8IPDS_PASPowerSupTime_RcvCnt
      ComRx_u8IPDS_PCUPowerSup: nonqueued-receiver-com-spec{data-element=ComRx_u8IPDS_PCUPowerSup/Val, filter=data-filter-type=ALWAYS, init-value=0}, required-interface=ComRx_u8IPDS_PCUPowerSup
      ComRx_u8IPDS_PCUPowerSupTime: nonqueued-receiver-com-spec{data-element=ComRx_u8IPDS_PCUPowerSupTime/Val, filter=data-filter-type=ALWAYS, init-value=0}, required-interface=ComRx_u8IPDS_PCUPowerSupTime
      ComRx_u8IPDS_PCUPowerSupTime_RcvCnt: nonqueued-receiver-com-spec{data-element=ComRx_u8IPDS_PCUPowerSupTime_RcvCnt/Val, filter=data-filter-type=ALWAYS, init-value=0}, required-interface=ComRx_u8IPDS_PCUPowerSupTime_RcvCnt
      ComRx_u8IPDS_Rear12VPowerSup: nonqueued-receiver-com-spec{data-element=ComRx_u8IPDS_Rear12VPowerSup/Val, filter=data-filter-type=ALWAYS, init-value=0}, required-interface=ComRx_u8IPDS_Rear12VPowerSup
      ComRx_u8IPDS_Rear12VPowerSupTime: nonqueued-receiver-com-spec{data-element=ComRx_u8IPDS_Rear12VPowerSupTime/Val, filter=data-filter-type=ALWAYS, init-value=0}, required-interface=ComRx_u8IPDS_Rear12VPowerSupTime
      ComRx_u8IPDS_Rear12VPowerSupTime_RcvCnt: nonqueued-receiver-com-spec{data-element=ComRx_u8IPDS_Rear12VPowerSupTime_RcvCnt/Val, filter=data-filter-type=ALWAYS, init-value=0}, required-interface=ComRx_u8IPDS_Rear12VPowerSupTime_RcvCnt
      ComRx_u8IPDS_RearBlowerPowerSup: nonqueued-receiver-com-spec{data-element=ComRx_u8IPDS_RearBlowerPowerSup/Val, filter=data-filter-type=ALWAYS, init-value=0}, required-interface=ComRx_u8IPDS_RearBlowerPowerSup
      ComRx_u8IPDS_RearBlowerPowerSupTime: nonqueued-receiver-com-spec{data-element=ComRx_u8IPDS_RearBlowerPowerSupTime/Val, filter=data-filter-type=ALWAYS, init-value=0}, required-interface=ComRx_u8IPDS_RearBlowerPowerSupTime
      ComRx_u8IPDS_RearBlowerPowerSupTime_RcvCnt: nonqueued-receiver-com-spec{data-element=ComRx_u8IPDS_RearBlowerPowerSupTime_RcvCnt/Val, filter=data-filter-type=ALWAYS, init-value=0}, required-interface=ComRx_u8IPDS_RearBlowerPowerSupTime_RcvCnt
      ComRx_u8IPDS_RearCtrlPanelPowerSup: nonqueued-receiver-com-spec{data-element=ComRx_u8IPDS_RearCtrlPanelPowerSup/Val, filter=data-filter-type=ALWAYS, init-value=0}, required-interface=ComRx_u8IPDS_RearCtrlPanelPowerSup
      ComRx_u8IPDS_RearCtrlPanelPowerSupTime: nonqueued-receiver-com-spec{data-element=ComRx_u8IPDS_RearCtrlPanelPowerSupTime/Val, filter=data-filter-type=ALWAYS, init-value=0}, required-interface=ComRx_u8IPDS_RearCtrlPanelPowerSupTime
      ComRx_u8IPDS_RearCtrlPanelPowerSupTime_RcvCnt: nonqueued-receiver-com-spec{data-element=ComRx_u8IPDS_RearCtrlPanelPowerSupTime_RcvCnt/Val, filter=data-filter-type=ALWAYS, init-value=0}, required-interface=ComRx_u8IPDS_RearCtrlPanelPowerSupTime_RcvCnt
      ComRx_u8IPDS_RearEOPPowerSup: nonqueued-receiver-com-spec{data-element=ComRx_u8IPDS_RearEOPPowerSup/Val, filter=data-filter-type=ALWAYS, init-value=0}, required-interface=ComRx_u8IPDS_RearEOPPowerSup
      ComRx_u8IPDS_RearEOPPowerSupTime: nonqueued-receiver-com-spec{data-element=ComRx_u8IPDS_RearEOPPowerSupTime/Val, filter=data-filter-type=ALWAYS, init-value=0}, required-interface=ComRx_u8IPDS_RearEOPPowerSupTime
      ComRx_u8IPDS_RearEOPPowerSupTime_RcvCnt: nonqueued-receiver-com-spec{data-element=ComRx_u8IPDS_RearEOPPowerSupTime_RcvCnt/Val, filter=data-filter-type=ALWAYS, init-value=0}, required-interface=ComRx_u8IPDS_RearEOPPowerSupTime_RcvCnt
      ComRx_u8IPDS_RearMotorPowerSup: nonqueued-receiver-com-spec{data-element=ComRx_u8IPDS_RearMotorPowerSup/Val, filter=data-filter-type=ALWAYS, init-value=0}, required-interface=ComRx_u8IPDS_RearMotorPowerSup
      ComRx_u8IPDS_RearMotorPowerSupTime: nonqueued-receiver-com-spec{data-element=ComRx_u8IPDS_RearMotorPowerSupTime/Val, filter=data-filter-type=ALWAYS, init-value=0}, required-interface=ComRx_u8IPDS_RearMotorPowerSupTime
      ComRx_u8IPDS_RearMotorPowerSupTime_RcvCnt: nonqueued-receiver-com-spec{data-element=ComRx_u8IPDS_RearMotorPowerSupTime_RcvCnt/Val, filter=data-filter-type=ALWAYS, init-value=0}, required-interface=ComRx_u8IPDS_RearMotorPowerSupTime_RcvCnt
      ComRx_u8IPDS_RearRadarPowerSup: nonqueued-receiver-com-spec{data-element=ComRx_u8IPDS_RearRadarPowerSup/Val, filter=data-filter-type=ALWAYS, init-value=0}, required-interface=ComRx_u8IPDS_RearRadarPowerSup
      ComRx_u8IPDS_RearRadarPowerSupTime: nonqueued-receiver-com-spec{data-element=ComRx_u8IPDS_RearRadarPowerSupTime/Val, filter=data-filter-type=ALWAYS, init-value=0}, required-interface=ComRx_u8IPDS_RearRadarPowerSupTime
      ComRx_u8IPDS_RearRadarPowerSupTime_RcvCnt: nonqueued-receiver-com-spec{data-element=ComRx_u8IPDS_RearRadarPowerSupTime_RcvCnt/Val, filter=data-filter-type=ALWAYS, init-value=0}, required-interface=ComRx_u8IPDS_RearRadarPowerSupTime_RcvCnt
      ComRx_u8IPDS_RLALampCtlUnitPowerSup: nonqueued-receiver-com-spec{data-element=ComRx_u8IPDS_RLALampCtlUnitPowerSup/Val, filter=data-filter-type=ALWAYS, init-value=0}, required-interface=ComRx_u8IPDS_RLALampCtlUnitPowerSup
      ComRx_u8IPDS_RLALampCtlUnitPowerSupTime: nonqueued-receiver-com-spec{data-element=ComRx_u8IPDS_RLALampCtlUnitPowerSupTime/Val, filter=data-filter-type=ALWAYS, init-value=0}, required-interface=ComRx_u8IPDS_RLALampCtlUnitPowerSupTime
      ComRx_u8IPDS_RLALampCtlUnitPowerSupTime_RcvCnt: nonqueued-receiver-com-spec{data-element=ComRx_u8IPDS_RLALampCtlUnitPowerSupTime_RcvCnt/Val, filter=data-filter-type=ALWAYS, init-value=0}, required-interface=ComRx_u8IPDS_RLALampCtlUnitPowerSupTime_RcvCnt
      ComRx_u8IPDS_RLBLampCtlUnitPowerSup: nonqueued-receiver-com-spec{data-element=ComRx_u8IPDS_RLBLampCtlUnitPowerSup/Val, filter=data-filter-type=ALWAYS, init-value=0}, required-interface=ComRx_u8IPDS_RLBLampCtlUnitPowerSup
      ComRx_u8IPDS_RLBLampCtlUnitPowerSupTime: nonqueued-receiver-com-spec{data-element=ComRx_u8IPDS_RLBLampCtlUnitPowerSupTime/Val, filter=data-filter-type=ALWAYS, init-value=0}, required-interface=ComRx_u8IPDS_RLBLampCtlUnitPowerSupTime
      ComRx_u8IPDS_RLBLampCtlUnitPowerSupTime_RcvCnt: nonqueued-receiver-com-spec{data-element=ComRx_u8IPDS_RLBLampCtlUnitPowerSupTime_RcvCnt/Val, filter=data-filter-type=ALWAYS, init-value=0}, required-interface=ComRx_u8IPDS_RLBLampCtlUnitPowerSupTime_RcvCnt
      ComRx_u8IPDS_RMPowerSup: nonqueued-receiver-com-spec{data-element=ComRx_u8IPDS_RMPowerSup/Val, filter=data-filter-type=ALWAYS, init-value=0}, required-interface=ComRx_u8IPDS_RMPowerSup
      ComRx_u8IPDS_RMPowerSupTime: nonqueued-receiver-com-spec{data-element=ComRx_u8IPDS_RMPowerSupTime/Val, filter=data-filter-type=ALWAYS, init-value=0}, required-interface=ComRx_u8IPDS_RMPowerSupTime
      ComRx_u8IPDS_RMPowerSupTime_RcvCnt: nonqueued-receiver-com-spec{data-element=ComRx_u8IPDS_RMPowerSupTime_RcvCnt/Val, filter=data-filter-type=ALWAYS, init-value=0}, required-interface=ComRx_u8IPDS_RMPowerSupTime_RcvCnt
      ComRx_u8IPDS_RRALampCtlUnitPowerSup: nonqueued-receiver-com-spec{data-element=ComRx_u8IPDS_RRALampCtlUnitPowerSup/Val, filter=data-filter-type=ALWAYS, init-value=0}, required-interface=ComRx_u8IPDS_RRALampCtlUnitPowerSup
      ComRx_u8IPDS_RRALampCtlUnitPowerSupTime: nonqueued-receiver-com-spec{data-element=ComRx_u8IPDS_RRALampCtlUnitPowerSupTime/Val, filter=data-filter-type=ALWAYS, init-value=0}, required-interface=ComRx_u8IPDS_RRALampCtlUnitPowerSupTime
      ComRx_u8IPDS_RRALampCtlUnitPowerSupTime_RcvCnt: nonqueued-receiver-com-spec{data-element=ComRx_u8IPDS_RRALampCtlUnitPowerSupTime_RcvCnt/Val, filter=data-filter-type=ALWAYS, init-value=0}, required-interface=ComRx_u8IPDS_RRALampCtlUnitPowerSupTime_RcvCnt
      ComRx_u8IPDS_RRBLampCtlUnitPowerSup: nonqueued-receiver-com-spec{data-element=ComRx_u8IPDS_RRBLampCtlUnitPowerSup/Val, filter=data-filter-type=ALWAYS, init-value=0}, required-interface=ComRx_u8IPDS_RRBLampCtlUnitPowerSup
      ComRx_u8IPDS_RRBLampCtlUnitPowerSupTime: nonqueued-receiver-com-spec{data-element=ComRx_u8IPDS_RRBLampCtlUnitPowerSupTime/Val, filter=data-filter-type=ALWAYS, init-value=0}, required-interface=ComRx_u8IPDS_RRBLampCtlUnitPowerSupTime
      ComRx_u8IPDS_RRBLampCtlUnitPowerSupTime_RcvCnt: nonqueued-receiver-com-spec{data-element=ComRx_u8IPDS_RRBLampCtlUnitPowerSupTime_RcvCnt/Val, filter=data-filter-type=ALWAYS, init-value=0}, required-interface=ComRx_u8IPDS_RRBLampCtlUnitPowerSupTime_RcvCnt
      ComRx_u8UMM_UsageModeSt: nonqueued-receiver-com-spec{data-element=ComRx_u8UMM_UsageModeSt/Val, filter=data-filter-type=ALWAYS, init-value=0}, required-interface=ComRx_u8UMM_UsageModeSt
      ComRx_u8VMM_OTAModeSt: nonqueued-receiver-com-spec{data-element=ComRx_u8VMM_OTAModeSt/Val, filter=data-filter-type=ALWAYS, init-value=0}, required-interface=ComRx_u8VMM_OTAModeSt
      gPRM_bPositionLightTimingOFFEnableCfg: nonqueued-receiver-com-spec{data-element=gPRM_bPositionLightTimingOFFEnableCfg/Val, filter=data-filter-type=ALWAYS, init-value=0}, required-interface=gPRM_bPositionLightTimingOFFEnableCfg
      gPRM_u8VehicleTypeCfg: nonqueued-receiver-com-spec{data-element=gPRM_u8VehicleTypeCfg/Val, filter=data-filter-type=ALWAYS, init-value=0}, required-interface=gPRM_u8VehicleTypeCfg
      gPRM_u8VehRLCM: nonqueued-receiver-com-spec{data-element=gPRM_u8VehRLCM/Val, filter=data-filter-type=ALWAYS, init-value=0}, required-interface=gPRM_u8VehRLCM
      NMW_tGetAllCurrentComModeRTE: client-com-spec=NMW_tGetAllCurrentComModeRTE/Operation, required-interface=NMW_tGetAllCurrentComModeRTE
      NMW_tGetCurrentComModeRTE: client-com-spec=NMW_tGetCurrentComModeRTE/Operation, required-interface=NMW_tGetCurrentComModeRTE
    behavior KL15PwrSply_ComCnvRx_InternalBehavior: data-type-mapping=[DTMS_ZCUTAdpr, DTMS_KL15PwrSplyComCnvRx]
      timing event TMT_KL15PwrSply_ComCnvRx_Runnable_10ms: start-on-event=KL15PwrSply_ComCnvRx_Runnable_10ms, period=0.01
      init event KL15PwrSply_ComCnvRx_Runnable_InitEvent: start-on-event=KL15PwrSply_ComCnvRx_Runnable_Init
      runnable KL15PwrSply_ComCnvRx_Runnable_10ms
        data-read-access:
          80 x access:
            READ_ComRx_bBCS_VehSpd_TiOut_Val: accessed-variable=ComRx_bBCS_VehSpd_TiOut.Val
            READ_ComRx_bBCS_VehSpdVD_TiOut_Val: accessed-variable=ComRx_bBCS_VehSpdVD_TiOut.Val
            READ_ComRx_bEL_PositionLightTimingOFFCfg_Val: accessed-variable=ComRx_bEL_PositionLightTimingOFFCfg.Val
            READ_ComRx_bEL_RLPositionLightCtrlCmd_Val: accessed-variable=ComRx_bEL_RLPositionLightCtrlCmd.Val
            READ_ComRx_bEL_RRPositionLightCtrlCmd_Val: accessed-variable=ComRx_bEL_RRPositionLightCtrlCmd.Val
            READ_ComRx_u8IPDS_AMPPowerSup_Val: accessed-variable=ComRx_u8IPDS_AMPPowerSup.Val
            READ_ComRx_u8IPDS_AMPPowerSupTime_RcvCnt_Val: accessed-variable=ComRx_u8IPDS_AMPPowerSupTime_RcvCnt.Val
            READ_ComRx_u8IPDS_InverterPowerSupTime_RcvCnt_Val: accessed-variable=ComRx_u8IPDS_InverterPowerSupTime_RcvCnt.Val
            READ_ComRx_u8IPDS_KL15T1PowerSupTime_RcvCnt_Val: accessed-variable=ComRx_u8IPDS_KL15T1PowerSupTime_RcvCnt.Val
            READ_ComRx_u8IPDS_KL15T2PowerSupTime_RcvCnt_Val: accessed-variable=ComRx_u8IPDS_KL15T2PowerSupTime_RcvCnt.Val
            READ_ComRx_u8IPDS_PASPowerSup_Val: accessed-variable=ComRx_u8IPDS_PASPowerSup.Val
            READ_ComRx_u8IPDS_PASPowerSupTime_RcvCnt_Val: accessed-variable=ComRx_u8IPDS_PASPowerSupTime_RcvCnt.Val
            READ_ComRx_u8IPDS_PASPowerSupTime_Val: accessed-variable=ComRx_u8IPDS_PASPowerSupTime.Val
            READ_ComRx_u8IPDS_PCUPowerSupTime_RcvCnt_Val: accessed-variable=ComRx_u8IPDS_PCUPowerSupTime_RcvCnt.Val
            READ_ComRx_u8IPDS_Rear12VPowerSupTime_RcvCnt_Val: accessed-variable=ComRx_u8IPDS_Rear12VPowerSupTime_RcvCnt.Val
            READ_ComRx_u8IPDS_RearBlowerPowerSupTime_RcvCnt_Val: accessed-variable=ComRx_u8IPDS_RearBlowerPowerSupTime_RcvCnt.Val
            READ_ComRx_u8IPDS_RearCtrlPanelPowerSupTime_RcvCnt_Val: accessed-variable=ComRx_u8IPDS_RearCtrlPanelPowerSupTime_RcvCnt.Val
            READ_ComRx_u8IPDS_RearEOPPowerSupTime_RcvCnt_Val: accessed-variable=ComRx_u8IPDS_RearEOPPowerSupTime_RcvCnt.Val
            READ_ComRx_u8IPDS_RearMotorPowerSupTime_RcvCnt_Val: accessed-variable=ComRx_u8IPDS_RearMotorPowerSupTime_RcvCnt.Val
            READ_ComRx_u8IPDS_RearRadarPowerSupTime_RcvCnt_Val: accessed-variable=ComRx_u8IPDS_RearRadarPowerSupTime_RcvCnt.Val
            READ_ComRx_u8IPDS_RLALampCtlUnitPowerSupTime_RcvCnt_Val: accessed-variable=ComRx_u8IPDS_RLALampCtlUnitPowerSupTime_RcvCnt.Val
            READ_ComRx_u8IPDS_RLBLampCtlUnitPowerSupTime_RcvCnt_Val: accessed-variable=ComRx_u8IPDS_RLBLampCtlUnitPowerSupTime_RcvCnt.Val
            READ_ComRx_u8IPDS_RMPowerSupTime_RcvCnt_Val: accessed-variable=ComRx_u8IPDS_RMPowerSupTime_RcvCnt.Val
            READ_ComRx_u8IPDS_RRALampCtlUnitPowerSupTime_RcvCnt_Val: accessed-variable=ComRx_u8IPDS_RRALampCtlUnitPowerSupTime_RcvCnt.Val
            READ_ComRx_u8IPDS_RRBLampCtlUnitPowerSupTime_RcvCnt_Val: accessed-variable=ComRx_u8IPDS_RRBLampCtlUnitPowerSupTime_RcvCnt.Val
            READ_ComRx_u8UMM_UsageModeSt_Val: accessed-variable=ComRx_u8UMM_UsageModeSt.Val
            READ_ComRx_u8VMM_OTAModeSt_Val: accessed-variable=ComRx_u8VMM_OTAModeSt.Val
            READ_gASI_bAMPPowerSup_TimeOut_Val: accessed-variable=ComRx_bIPDS_AMPPowerSup_TiOut.Val
            READ_gASI_bInverterPowerSup_TimeOut_Val: accessed-variable=ComRx_bIPDS_InverterPowerSup_TiOut.Val
            READ_gASI_bKL15T1PowerSup_TimeOut_Val: accessed-variable=ComRx_bIPDS_KL15T1PowerSup_TiOut.Val
            READ_gASI_bKL15T2PowerSup_TimeOut_Val: accessed-variable=ComRx_bIPDS_KL15T2PowerSup_TiOut.Val
            READ_gASI_bPCUPowerSup_TimeOut_Val: accessed-variable=ComRx_bIPDS_PCUPowerSup_TiOut.Val
            READ_gASI_bRear12VPowerSup_TimeOut_Val: accessed-variable=ComRx_bIPDS_Rear12VPowerSup_TiOut.Val
            READ_gASI_bRearBlowerPowerSup_TimeOut_Val: accessed-variable=ComRx_bIPDS_RearBlowerPowerSup_TiOut.Val
            READ_gASI_bRearCtrlPanelPowerSup_TimeOut_Val: accessed-variable=ComRx_bIPDS_RearCtrlPanelPowerSup_TiOut.Val
            READ_gASI_bRearEOPPowerSup_TimeOut_Val: accessed-variable=ComRx_bIPDS_RearEOPPowerSup_TiOut.Val
            READ_gASI_bRearMotorPowerSup_TimeOut_Val: accessed-variable=ComRx_bIPDS_RearMotorPowerSup_TiOut.Val
            READ_gASI_bRearRadarPowerSup_TimeOut_Val: accessed-variable=ComRx_bIPDS_RearRadarPowerSup_TiOut.Val
            READ_gASI_bRLALampCtlUnitPowerSup_TimeOut_Val: accessed-variable=ComRx_bIPDS_RLALampCtlUnitPowerSup_TiOut.Val
            READ_gASI_bRLBLampCtlUnitPowerSup_TimeOut_Val: accessed-variable=ComRx_bIPDS_RLBLampCtlUnitPowerSup_TiOut.Val
            READ_gASI_bRMPowerSup_TimeOut_Val: accessed-variable=ComRx_bIPDS_RMPowerSup_TiOut.Val
            READ_gASI_bRRALampCtlUnitPowerSup_TimeOut_Val: accessed-variable=ComRx_bIPDS_RRALampCtlUnitPowerSup_TiOut.Val
            READ_gASI_bRRBLampCtlUnitPowerSup_TimeOut_Val: accessed-variable=ComRx_bIPDS_RRBLampCtlUnitPowerSup_TiOut.Val
            READ_gASI_bUsageModeSt_TimeOut_Val: accessed-variable=ComRx_bUMM_UsageModeSt_TiOut.Val
            READ_gCAN_bBCS_VehSpdVD_Val: accessed-variable=ComRx_bBCS_VehSpdVD.Val
            READ_gCAN_u16BCS_VehSpd_Val: accessed-variable=ComRx_u16BCS_VehSpd.Val
            READ_gCAN_u8AMPPowerSupTime_Val: accessed-variable=ComRx_u8IPDS_AMPPowerSupTime.Val
            READ_gCAN_u8InverterPowerSup_Val: accessed-variable=ComRx_u8IPDS_InverterPowerSup.Val
            READ_gCAN_u8InverterPowerSupTime_Val: accessed-variable=ComRx_u8IPDS_InverterPowerSupTime.Val
            READ_gCAN_u8KL15T1PowerSup_Val: accessed-variable=ComRx_u8IPDS_KL15T1PowerSup.Val
            READ_gCAN_u8KL15T1PowerSupTime_Val: accessed-variable=ComRx_u8IPDS_KL15T1PowerSupTime.Val
            READ_gCAN_u8KL15T2PowerSup_Val: accessed-variable=ComRx_u8IPDS_KL15T2PowerSup.Val
            READ_gCAN_u8KL15T2PowerSupTime_Val: accessed-variable=ComRx_u8IPDS_KL15T2PowerSupTime.Val
            READ_gCAN_u8PCUPowerSup_Val: accessed-variable=ComRx_u8IPDS_PCUPowerSup.Val
            READ_gCAN_u8PCUPowerSupTime_Val: accessed-variable=ComRx_u8IPDS_PCUPowerSupTime.Val
            READ_gCAN_u8Rear12VPowerSup_Val: accessed-variable=ComRx_u8IPDS_Rear12VPowerSup.Val
            READ_gCAN_u8Rear12VPowerSupTime_Val: accessed-variable=ComRx_u8IPDS_Rear12VPowerSupTime.Val
            READ_gCAN_u8RearBlowerPowerSup_Val: accessed-variable=ComRx_u8IPDS_RearBlowerPowerSup.Val
            READ_gCAN_u8RearBlowerPowerSupTime_Val: accessed-variable=ComRx_u8IPDS_RearBlowerPowerSupTime.Val
            READ_gCAN_u8RearCtrlPanelPowerSup_Val: accessed-variable=ComRx_u8IPDS_RearCtrlPanelPowerSup.Val
            READ_gCAN_u8RearCtrlPanelPowerSupTime_Val: accessed-variable=ComRx_u8IPDS_RearCtrlPanelPowerSupTime.Val
            READ_gCAN_u8RearEOPPowerSup_Val: accessed-variable=ComRx_u8IPDS_RearEOPPowerSup.Val
            READ_gCAN_u8RearEOPPowerSupTime_Val: accessed-variable=ComRx_u8IPDS_RearEOPPowerSupTime.Val
            READ_gCAN_u8RearMotorPowerSup_Val: accessed-variable=ComRx_u8IPDS_RearMotorPowerSup.Val
            READ_gCAN_u8RearMotorPowerSupTime_Val: accessed-variable=ComRx_u8IPDS_RearMotorPowerSupTime.Val
            READ_gCAN_u8RearRadarPowerSup_Val: accessed-variable=ComRx_u8IPDS_RearRadarPowerSup.Val
            READ_gCAN_u8RearRadarPowerSupTime_Val: accessed-variable=ComRx_u8IPDS_RearRadarPowerSupTime.Val
            READ_gCAN_u8RLALampCtlUnitPowerSup_Val: accessed-variable=ComRx_u8IPDS_RLALampCtlUnitPowerSup.Val
            READ_gCAN_u8RLALampCtlUnitPowerSupTime_Val: accessed-variable=ComRx_u8IPDS_RLALampCtlUnitPowerSupTime.Val
            READ_gCAN_u8RLBLampCtlUnitPowerSup_Val: accessed-variable=ComRx_u8IPDS_RLBLampCtlUnitPowerSup.Val
            READ_gCAN_u8RLBLampCtlUnitPowerSupTime_Val: accessed-variable=ComRx_u8IPDS_RLBLampCtlUnitPowerSupTime.Val
            READ_gCAN_u8RMPowerSup_Val: accessed-variable=ComRx_u8IPDS_RMPowerSup.Val
            READ_gCAN_u8RMPowerSupTime_Val: accessed-variable=ComRx_u8IPDS_RMPowerSupTime.Val
            READ_gCAN_u8RRALampCtlUnitPowerSup_Val: accessed-variable=ComRx_u8IPDS_RRALampCtlUnitPowerSup.Val
            READ_gCAN_u8RRALampCtlUnitPowerSupTime_Val: accessed-variable=ComRx_u8IPDS_RRALampCtlUnitPowerSupTime.Val
            READ_gCAN_u8RRBLampCtlUnitPowerSup_Val: accessed-variable=ComRx_u8IPDS_RRBLampCtlUnitPowerSup.Val
            READ_gCAN_u8RRBLampCtlUnitPowerSupTime_Val: accessed-variable=ComRx_u8IPDS_RRBLampCtlUnitPowerSupTime.Val
            READ_gPRM_bPositionLightTimingOFFEnableCfg_Val: accessed-variable=gPRM_bPositionLightTimingOFFEnableCfg.Val
            READ_gPRM_u8VehicleTypeCfg_Val: accessed-variable=gPRM_u8VehicleTypeCfg.Val
            READ_gPRM_u8VehRLCM_Val: accessed-variable=gPRM_u8VehRLCM.Val
        data-write-access:
          15 x access:
            WRITE_PwrSply_au8PwrSup_Val: accessed-variable=PwrSply_au8PwrSup.Val
            WRITE_PwrSply_au8PwrSupTime_RcvCnt_Val: accessed-variable=PwrSply_au8PwrSupTime_RcvCnt.Val
            WRITE_PwrSply_au8PwrSupTime_Val: accessed-variable=PwrSply_au8PwrSupTime.Val
            WRITE_PwrSply_bCCULostComm_Val: accessed-variable=PwrSply_bCCULostComm.Val
            WRITE_PwrSply_bNetSleepFlag_Val: accessed-variable=PwrSply_bNetSleepFlag.Val
            WRITE_PwrSply_bPositionLightCtrlCmd{01..04}_Val: accessed-variable=PwrSply_bPositionLightCtrlCmd{01..04}.Val
            WRITE_PwrSply_bPositionLightTimingOFFEnableCfg_Val: accessed-variable=PwrSply_bPositionLightTimingOFFEnableCfg.Val
            WRITE_PwrSply_bVehSpdTkOvr_Val: accessed-variable=PwrSply_bVehSpdTkOvr.Val
            WRITE_PwrSply_u8UMM_UsageModeSt_Val: accessed-variable=PwrSply_u8UMM_UsageModeSt.Val
            WRITE_PwrSply_u8VehicleTypeCfg_Val: accessed-variable=PwrSply_u8VehicleTypeCfg.Val
            WRITE_PwrSply_u8VehRLCM_Val: accessed-variable=PwrSply_u8VehRLCM.Val
            WRITE_PwrSply_u8VMM_OTAModeSt_Val: accessed-variable=PwrSply_u8VMM_OTAModeSt.Val
        sync call SC_NMW_tGetAllCurrentComModeRTE_Operation: operation=NMW_tGetAllCurrentComModeRTE.Operation, timeout=0
        sync call SC_NMW_tGetCurrentComModeRTE_Operation: operation=NMW_tGetCurrentComModeRTE.Operation, timeout=0
      runnable KL15PwrSply_ComCnvRx_Runnable_Init
        data-write-access:
          15 x access:
            WRITE_PwrSply_au8PwrSup_Val: accessed-variable=PwrSply_au8PwrSup.Val
            WRITE_PwrSply_au8PwrSupTime_RcvCnt_Val: accessed-variable=PwrSply_au8PwrSupTime_RcvCnt.Val
            WRITE_PwrSply_au8PwrSupTime_Val: accessed-variable=PwrSply_au8PwrSupTime.Val
            WRITE_PwrSply_bCCULostComm_Val: accessed-variable=PwrSply_bCCULostComm.Val
            WRITE_PwrSply_bNetSleepFlag_Val: accessed-variable=PwrSply_bNetSleepFlag.Val
            WRITE_PwrSply_bPositionLightCtrlCmd{01..04}_Val: accessed-variable=PwrSply_bPositionLightCtrlCmd{01..04}.Val
            WRITE_PwrSply_bPositionLightTimingOFFEnableCfg_Val: accessed-variable=PwrSply_bPositionLightTimingOFFEnableCfg.Val
            WRITE_PwrSply_bVehSpdTkOvr_Val: accessed-variable=PwrSply_bVehSpdTkOvr.Val
            WRITE_PwrSply_u8UMM_UsageModeSt_Val: accessed-variable=PwrSply_u8UMM_UsageModeSt.Val
            WRITE_PwrSply_u8VehicleTypeCfg_Val: accessed-variable=PwrSply_u8VehicleTypeCfg.Val
            WRITE_PwrSply_u8VehRLCM_Val: accessed-variable=PwrSply_u8VehRLCM.Val
            WRITE_PwrSply_u8VMM_OTAModeSt_Val: accessed-variable=PwrSply_u8VMM_OTAModeSt.Val
  swc implementation KL15PwrSply_ComCnvRx_Implementation: behavior=KL15PwrSply_ComCnvRx_InternalBehavior
    code-descriptors:
      code Default: artifact-descriptors=autosar-engineering-object={short-label=Default, category=SWSRC}
package /UAES/ASW/Units
  unit Curr_A: display-name=A, factor-si-to-unit=1, offset-si-to-unit=0
  unit NoUnit: factor-si-to-unit=1, offset-si-to-unit=0
